VERSION ""

NS_ :

BS_:

BU_:

BO_ 2568814450 Sevcon_2_HS5: 8 Vector__XXX
 SG_ Sevcon_2_EncoderAngle : 0|32@1- (0.00001525,0) [0|0] "" Vector__XXX

BO_ 2568683378 Sevcon_2_HS3: 8 Vector__XXX
 SG_ Sevcon_2_HeatSinkTemp : 0|16@1- (1,0) [0|0] "" Vector__XXX
 SG_ Sevcon_2_RemainingTemp : 16|16@1- (1,0) [0|0] "" Vector__XXX
 SG_ Sevcon_2_CapVoltage : 32|16@1- (0.0625,0) [0|0] "" Vector__XXX

BO_ 2568617842 Sevcon_2_HS2: 8 Vector__XXX
 SG_ Sevcon_2_StatusWord : 32|16@1- (1,0) [0|0] "" Vector__XXX

BO_ 2568552306 Sevcon_2_HS1: 8 Vector__XXX
 SG_ Sevcon_2_OutputTorque : 0|16@1- (0.0625,0) [0|0] "" Vector__XXX
 SG_ Sevcon_2_Speed : 16|16@1- (1,0) [0|0] "" Vector__XXX
 SG_ Sevcon_2_BatteryCurrent : 32|16@1- (1,0) [0|0] "" Vector__XXX

BO_ 2568814449 Sevcon_1_HS5: 8 Vector__XXX
 SG_ Sevcon_1_EncoderAngle : 0|32@1- (0.00001525,0) [0|0] "" Vector__XXX

BO_ 2568683377 Sevcon_1_HS3: 8 Vector__XXX
 SG_ Sevcon_1_HeatSinkTemp : 0|16@1- (1,0) [0|0] "" Vector__XXX
 SG_ Sevcon_1_RemainingTemp : 16|16@1- (1,0) [0|0] "" Vector__XXX
 SG_ Sevcon_1_CapVoltage : 32|16@1- (0.0625,0) [0|0] "" Vector__XXX

BO_ 2568617841 Sevcon_1_HS2: 8 Vector__XXX
 SG_ Sevcon_1_StatusWord : 32|16@1- (1,0) [0|0] "" Vector__XXX

BO_ 2568552305 Sevcon_1_HS1: 8 Vector__XXX
 SG_ Sevcon_1_OutputTorque : 0|16@1- (0.0625,0) [0|0] "" Vector__XXX
 SG_ Sevcon_1_Speed : 16|16@1- (1,0) [0|0] "" Vector__XXX
 SG_ Sevcon_1_BatteryCurrent : 32|16@1- (1,0) [0|0] "" Vector__XXX

BO_ 2290122920 VCU_Temp_Gearbox_Right: 8 Vector__XXX
 SG_ VCU_Gearbox_Temp_Right_Temp : 39|16@0+ (1,0) [0|0] "" Vector__XXX
 SG_ VCU_Gearbox_Temp_Right_R : 23|16@0+ (1,0) [0|0] "" Vector__XXX
 SG_ VCU_Gearbox_Temp_Right_ADC : 7|16@0+ (1,0) [0|0] "" Vector__XXX

BO_ 2290122919 VCU_Temp_Gearbox_Left: 8 Vector__XXX
 SG_ VCU_Gearbox_Temp_Left_Temp : 39|16@0+ (1,0) [0|0] "" Vector__XXX
 SG_ VCU_Gearbox_Temp_Left_R : 23|16@0+ (1,0) [0|0] "" Vector__XXX
 SG_ VCU_Gearbox_Temp_Left_ADC : 7|16@0+ (1,0) [0|0] "" Vector__XXX

BO_ 2290122832 VCU_AirPressure: 8 Vector__XXX
 SG_ VCU_AirPressure_ADC : 7|16@0+ (1,0) [0|0] "" Vector__XXX

BO_ 2420424705 MCISO_Heartbeat_Right: 8 Vector__XXX
 SG_ MCISO_HeartbeatState_Right : 0|16@1+ (1,0) [0|0] "" Vector__XXX

BO_ 2420424704 MCISO_Heartbeat_Left: 8 Vector__XXX
 SG_ MCISO_HeartbeatState_Left : 0|16@1+ (1,0) [0|0] "" Vector__XXX

BO_ 2424619008 SW_Heartbeat: 8 Vector__XXX
 SG_ SW_Heartbeat_Flags : 16|16@1+ (1,0) [0|0] "" Vector__XXX
 SG_ SW_Heartbeat_State : 0|8@1+ (1,0) [0|0] "" Vector__XXX
 SG_ SW_Heartbeat_MissionID : 8|8@1+ (1,0) [0|0] "" Vector__XXX

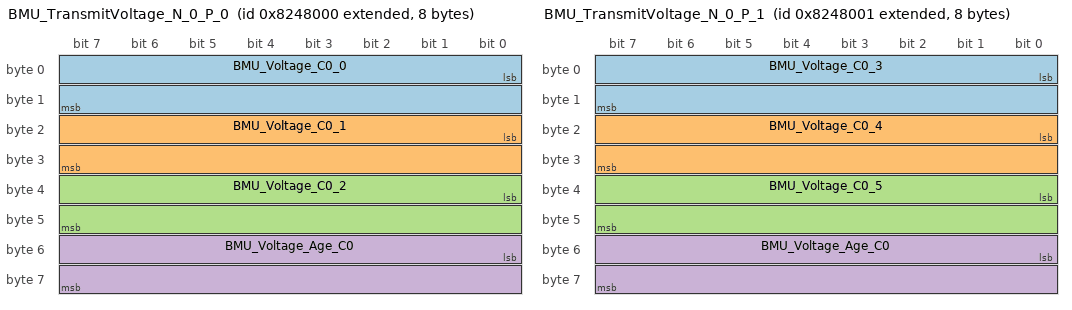
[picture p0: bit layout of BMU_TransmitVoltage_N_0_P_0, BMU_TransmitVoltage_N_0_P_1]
BO_ 2284093440 BMU_TransmitVoltage_N_0_P_0: 8 Vector__XXX
 SG_ BMU_Voltage_C0_0 : 0|16@1+ (1,0) [0|0] "" Vector__XXX
 SG_ BMU_Voltage_C0_1 : 16|16@1+ (1,0) [0|0] "" Vector__XXX
 SG_ BMU_Voltage_C0_2 : 32|16@1+ (1,0) [0|0] "" Vector__XXX
 SG_ BMU_Voltage_Age_C0 : 48|16@1+ (1,0) [0|0] "" Vector__XXX

BO_ 2284093441 BMU_TransmitVoltage_N_0_P_1: 8 Vector__XXX
 SG_ BMU_Voltage_C0_3 : 0|16@1+ (1,0) [0|0] "" Vector__XXX
 SG_ BMU_Voltage_C0_4 : 16|16@1+ (1,0) [0|0] "" Vector__XXX
 SG_ BMU_Voltage_C0_5 : 32|16@1+ (1,0) [0|0] "" Vector__XXX
 SG_ BMU_Voltage_Age_C0 : 48|16@1+ (1,0) [0|0] "" Vector__XXX

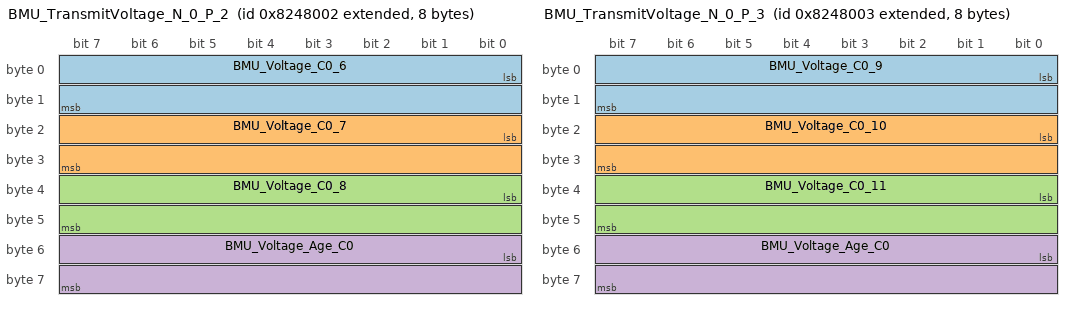
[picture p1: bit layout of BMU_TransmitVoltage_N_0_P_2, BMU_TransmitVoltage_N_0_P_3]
BO_ 2284093442 BMU_TransmitVoltage_N_0_P_2: 8 Vector__XXX
 SG_ BMU_Voltage_C0_6 : 0|16@1+ (1,0) [0|0] "" Vector__XXX
 SG_ BMU_Voltage_C0_7 : 16|16@1+ (1,0) [0|0] "" Vector__XXX
 SG_ BMU_Voltage_C0_8 : 32|16@1+ (1,0) [0|0] "" Vector__XXX
 SG_ BMU_Voltage_Age_C0 : 48|16@1+ (1,0) [0|0] "" Vector__XXX

BO_ 2284093443 BMU_TransmitVoltage_N_0_P_3: 8 Vector__XXX
 SG_ BMU_Voltage_C0_9 : 0|16@1+ (1,0) [0|0] "" Vector__XXX
 SG_ BMU_Voltage_C0_10 : 16|16@1+ (1,0) [0|0] "" Vector__XXX
 SG_ BMU_Voltage_C0_11 : 32|16@1+ (1,0) [0|0] "" Vector__XXX
 SG_ BMU_Voltage_Age_C0 : 48|16@1+ (1,0) [0|0] "" Vector__XXX

BO_ 2284093444 BMU_TransmitVoltage_N_0_P_4: 8 Vector__XXX
 SG_ BMU_Voltage_C0_12 : 0|16@1+ (1,0) [0|0] "" Vector__XXX
 SG_ BMU_Voltage_C0_13 : 16|16@1+ (1,0) [0|0] "" Vector__XXX
 SG_ BMU_Voltage_Age_C0 : 48|16@1+ (1,0) [0|0] "" Vector__XXX

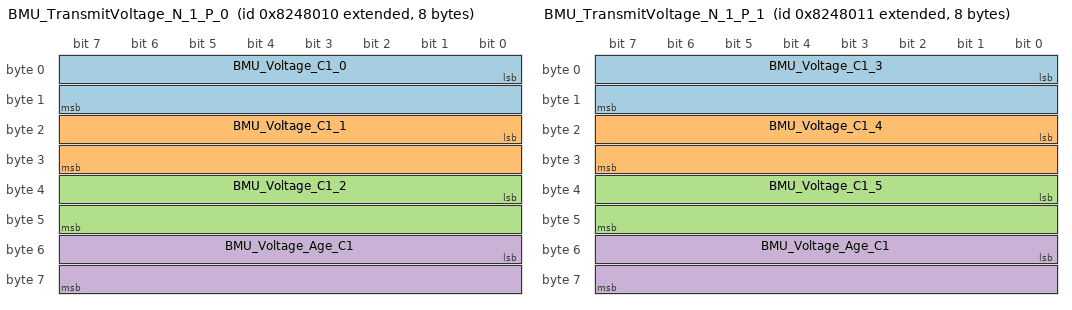
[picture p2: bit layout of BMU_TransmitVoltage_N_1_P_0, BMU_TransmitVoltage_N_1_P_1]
BO_ 2284093456 BMU_TransmitVoltage_N_1_P_0: 8 Vector__XXX
 SG_ BMU_Voltage_C1_0 : 0|16@1+ (1,0) [0|0] "" Vector__XXX
 SG_ BMU_Voltage_C1_1 : 16|16@1+ (1,0) [0|0] "" Vector__XXX
 SG_ BMU_Voltage_C1_2 : 32|16@1+ (1,0) [0|0] "" Vector__XXX
 SG_ BMU_Voltage_Age_C1 : 48|16@1+ (1,0) [0|0] "" Vector__XXX

BO_ 2284093457 BMU_TransmitVoltage_N_1_P_1: 8 Vector__XXX
 SG_ BMU_Voltage_C1_3 : 0|16@1+ (1,0) [0|0] "" Vector__XXX
 SG_ BMU_Voltage_C1_4 : 16|16@1+ (1,0) [0|0] "" Vector__XXX
 SG_ BMU_Voltage_C1_5 : 32|16@1+ (1,0) [0|0] "" Vector__XXX
 SG_ BMU_Voltage_Age_C1 : 48|16@1+ (1,0) [0|0] "" Vector__XXX

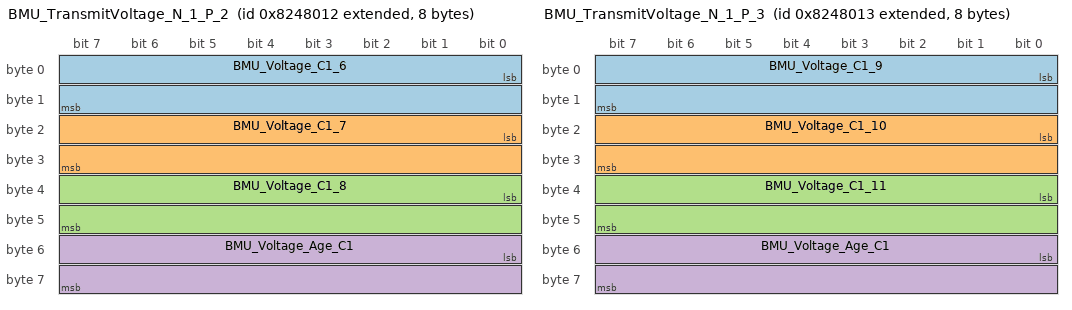
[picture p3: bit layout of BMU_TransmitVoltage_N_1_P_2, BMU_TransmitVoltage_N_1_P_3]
BO_ 2284093458 BMU_TransmitVoltage_N_1_P_2: 8 Vector__XXX
 SG_ BMU_Voltage_C1_6 : 0|16@1+ (1,0) [0|0] "" Vector__XXX
 SG_ BMU_Voltage_C1_7 : 16|16@1+ (1,0) [0|0] "" Vector__XXX
 SG_ BMU_Voltage_C1_8 : 32|16@1+ (1,0) [0|0] "" Vector__XXX
 SG_ BMU_Voltage_Age_C1 : 48|16@1+ (1,0) [0|0] "" Vector__XXX

BO_ 2284093459 BMU_TransmitVoltage_N_1_P_3: 8 Vector__XXX
 SG_ BMU_Voltage_C1_9 : 0|16@1+ (1,0) [0|0] "" Vector__XXX
 SG_ BMU_Voltage_C1_10 : 16|16@1+ (1,0) [0|0] "" Vector__XXX
 SG_ BMU_Voltage_C1_11 : 32|16@1+ (1,0) [0|0] "" Vector__XXX
 SG_ BMU_Voltage_Age_C1 : 48|16@1+ (1,0) [0|0] "" Vector__XXX

BO_ 2284093460 BMU_TransmitVoltage_N_1_P_4: 8 Vector__XXX
 SG_ BMU_Voltage_C1_12 : 0|16@1+ (1,0) [0|0] "" Vector__XXX
 SG_ BMU_Voltage_C1_13 : 16|16@1+ (1,0) [0|0] "" Vector__XXX
 SG_ BMU_Voltage_Age_C1 : 48|16@1+ (1,0) [0|0] "" Vector__XXX

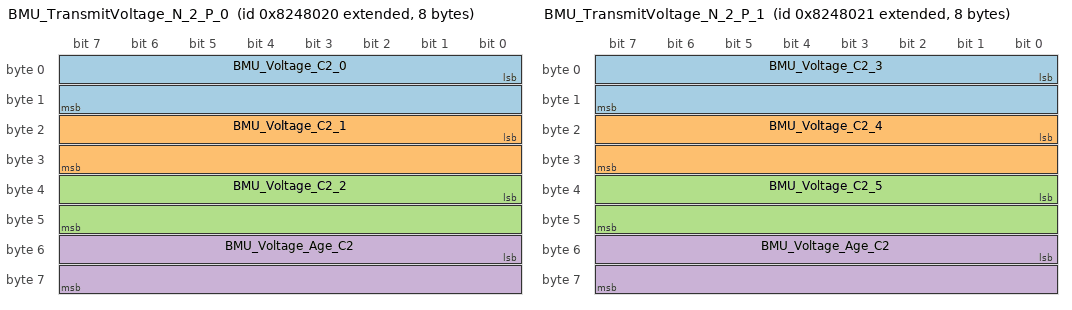
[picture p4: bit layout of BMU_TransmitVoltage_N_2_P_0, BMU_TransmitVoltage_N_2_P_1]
BO_ 2284093472 BMU_TransmitVoltage_N_2_P_0: 8 Vector__XXX
 SG_ BMU_Voltage_C2_0 : 0|16@1+ (1,0) [0|0] "" Vector__XXX
 SG_ BMU_Voltage_C2_1 : 16|16@1+ (1,0) [0|0] "" Vector__XXX
 SG_ BMU_Voltage_C2_2 : 32|16@1+ (1,0) [0|0] "" Vector__XXX
 SG_ BMU_Voltage_Age_C2 : 48|16@1+ (1,0) [0|0] "" Vector__XXX

BO_ 2284093473 BMU_TransmitVoltage_N_2_P_1: 8 Vector__XXX
 SG_ BMU_Voltage_C2_3 : 0|16@1+ (1,0) [0|0] "" Vector__XXX
 SG_ BMU_Voltage_C2_4 : 16|16@1+ (1,0) [0|0] "" Vector__XXX
 SG_ BMU_Voltage_C2_5 : 32|16@1+ (1,0) [0|0] "" Vector__XXX
 SG_ BMU_Voltage_Age_C2 : 48|16@1+ (1,0) [0|0] "" Vector__XXX

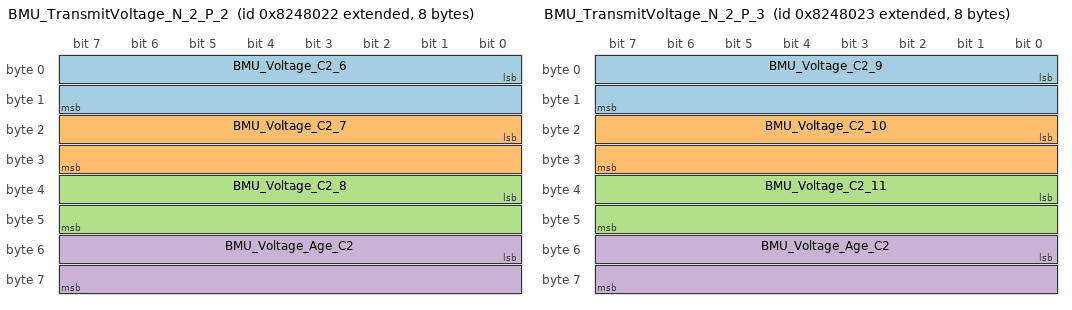
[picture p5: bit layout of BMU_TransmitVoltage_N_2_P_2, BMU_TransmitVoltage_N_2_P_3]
BO_ 2284093474 BMU_TransmitVoltage_N_2_P_2: 8 Vector__XXX
 SG_ BMU_Voltage_C2_6 : 0|16@1+ (1,0) [0|0] "" Vector__XXX
 SG_ BMU_Voltage_C2_7 : 16|16@1+ (1,0) [0|0] "" Vector__XXX
 SG_ BMU_Voltage_C2_8 : 32|16@1+ (1,0) [0|0] "" Vector__XXX
 SG_ BMU_Voltage_Age_C2 : 48|16@1+ (1,0) [0|0] "" Vector__XXX

BO_ 2284093475 BMU_TransmitVoltage_N_2_P_3: 8 Vector__XXX
 SG_ BMU_Voltage_C2_9 : 0|16@1+ (1,0) [0|0] "" Vector__XXX
 SG_ BMU_Voltage_C2_10 : 16|16@1+ (1,0) [0|0] "" Vector__XXX
 SG_ BMU_Voltage_C2_11 : 32|16@1+ (1,0) [0|0] "" Vector__XXX
 SG_ BMU_Voltage_Age_C2 : 48|16@1+ (1,0) [0|0] "" Vector__XXX

BO_ 2284093476 BMU_TransmitVoltage_N_2_P_4: 8 Vector__XXX
 SG_ BMU_Voltage_C2_12 : 0|16@1+ (1,0) [0|0] "" Vector__XXX
 SG_ BMU_Voltage_C2_13 : 16|16@1+ (1,0) [0|0] "" Vector__XXX
 SG_ BMU_Voltage_Age_C2 : 48|16@1+ (1,0) [0|0] "" Vector__XXX

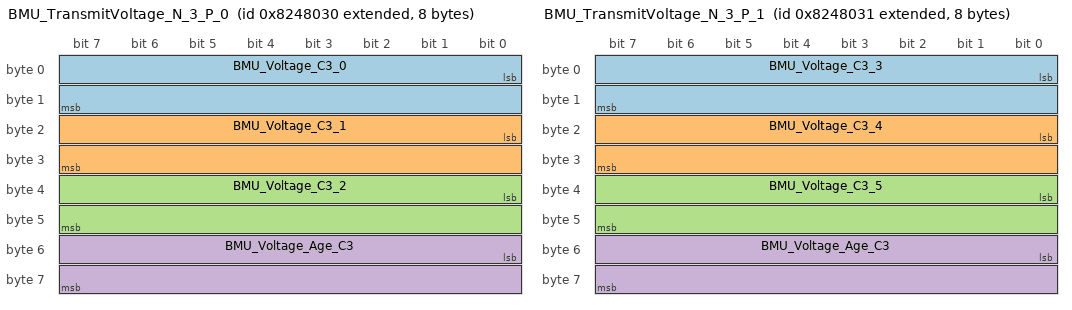
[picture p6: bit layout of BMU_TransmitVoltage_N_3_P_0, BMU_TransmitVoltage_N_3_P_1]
BO_ 2284093488 BMU_TransmitVoltage_N_3_P_0: 8 Vector__XXX
 SG_ BMU_Voltage_C3_0 : 0|16@1+ (1,0) [0|0] "" Vector__XXX
 SG_ BMU_Voltage_C3_1 : 16|16@1+ (1,0) [0|0] "" Vector__XXX
 SG_ BMU_Voltage_C3_2 : 32|16@1+ (1,0) [0|0] "" Vector__XXX
 SG_ BMU_Voltage_Age_C3 : 48|16@1+ (1,0) [0|0] "" Vector__XXX

BO_ 2284093489 BMU_TransmitVoltage_N_3_P_1: 8 Vector__XXX
 SG_ BMU_Voltage_C3_3 : 0|16@1+ (1,0) [0|0] "" Vector__XXX
 SG_ BMU_Voltage_C3_4 : 16|16@1+ (1,0) [0|0] "" Vector__XXX
 SG_ BMU_Voltage_C3_5 : 32|16@1+ (1,0) [0|0] "" Vector__XXX
 SG_ BMU_Voltage_Age_C3 : 48|16@1+ (1,0) [0|0] "" Vector__XXX

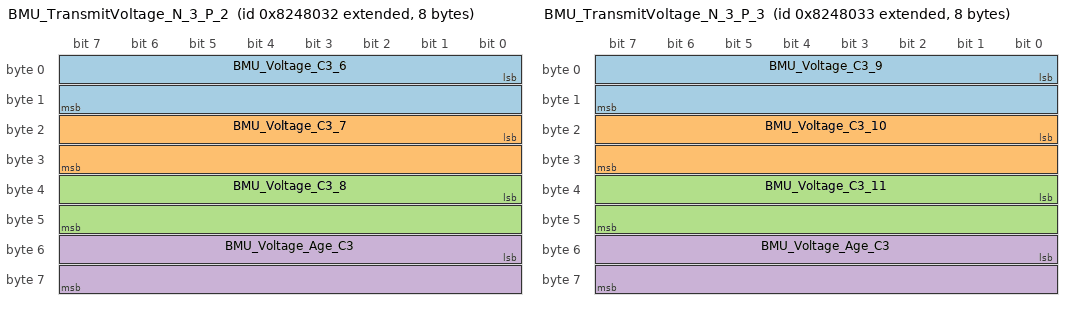
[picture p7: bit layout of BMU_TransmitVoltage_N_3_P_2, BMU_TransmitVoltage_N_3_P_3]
BO_ 2284093490 BMU_TransmitVoltage_N_3_P_2: 8 Vector__XXX
 SG_ BMU_Voltage_C3_6 : 0|16@1+ (1,0) [0|0] "" Vector__XXX
 SG_ BMU_Voltage_C3_7 : 16|16@1+ (1,0) [0|0] "" Vector__XXX
 SG_ BMU_Voltage_C3_8 : 32|16@1+ (1,0) [0|0] "" Vector__XXX
 SG_ BMU_Voltage_Age_C3 : 48|16@1+ (1,0) [0|0] "" Vector__XXX

BO_ 2284093491 BMU_TransmitVoltage_N_3_P_3: 8 Vector__XXX
 SG_ BMU_Voltage_C3_9 : 0|16@1+ (1,0) [0|0] "" Vector__XXX
 SG_ BMU_Voltage_C3_10 : 16|16@1+ (1,0) [0|0] "" Vector__XXX
 SG_ BMU_Voltage_C3_11 : 32|16@1+ (1,0) [0|0] "" Vector__XXX
 SG_ BMU_Voltage_Age_C3 : 48|16@1+ (1,0) [0|0] "" Vector__XXX

BO_ 2284093492 BMU_TransmitVoltage_N_3_P_4: 8 Vector__XXX
 SG_ BMU_Voltage_C3_12 : 0|16@1+ (1,0) [0|0] "" Vector__XXX
 SG_ BMU_Voltage_C3_13 : 16|16@1+ (1,0) [0|0] "" Vector__XXX
 SG_ BMU_Voltage_Age_C3 : 48|16@1+ (1,0) [0|0] "" Vector__XXX

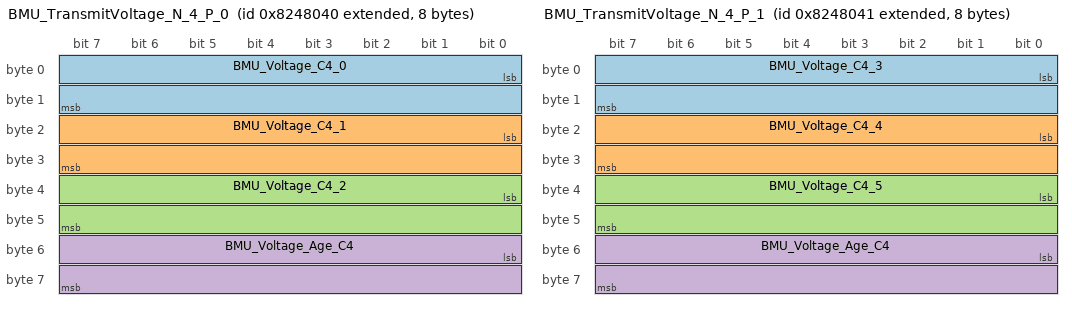
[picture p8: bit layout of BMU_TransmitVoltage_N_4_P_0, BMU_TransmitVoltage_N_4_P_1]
BO_ 2284093504 BMU_TransmitVoltage_N_4_P_0: 8 Vector__XXX
 SG_ BMU_Voltage_C4_0 : 0|16@1+ (1,0) [0|0] "" Vector__XXX
 SG_ BMU_Voltage_C4_1 : 16|16@1+ (1,0) [0|0] "" Vector__XXX
 SG_ BMU_Voltage_C4_2 : 32|16@1+ (1,0) [0|0] "" Vector__XXX
 SG_ BMU_Voltage_Age_C4 : 48|16@1+ (1,0) [0|0] "" Vector__XXX

BO_ 2284093505 BMU_TransmitVoltage_N_4_P_1: 8 Vector__XXX
 SG_ BMU_Voltage_C4_3 : 0|16@1+ (1,0) [0|0] "" Vector__XXX
 SG_ BMU_Voltage_C4_4 : 16|16@1+ (1,0) [0|0] "" Vector__XXX
 SG_ BMU_Voltage_C4_5 : 32|16@1+ (1,0) [0|0] "" Vector__XXX
 SG_ BMU_Voltage_Age_C4 : 48|16@1+ (1,0) [0|0] "" Vector__XXX

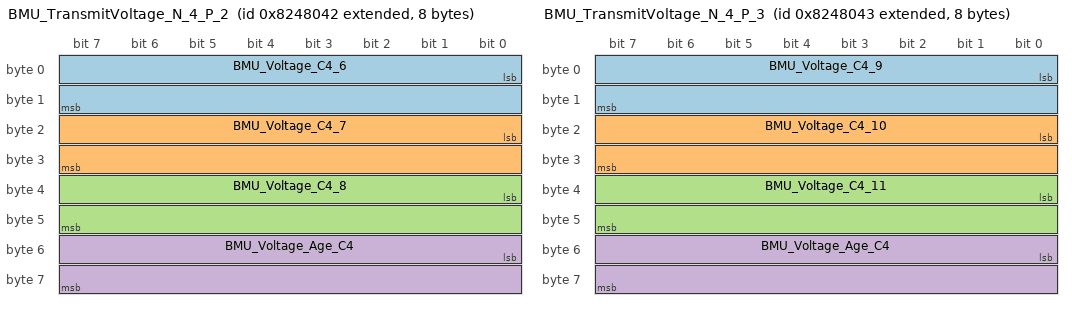
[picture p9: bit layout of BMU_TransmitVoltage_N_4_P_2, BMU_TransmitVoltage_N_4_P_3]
BO_ 2284093506 BMU_TransmitVoltage_N_4_P_2: 8 Vector__XXX
 SG_ BMU_Voltage_C4_6 : 0|16@1+ (1,0) [0|0] "" Vector__XXX
 SG_ BMU_Voltage_C4_7 : 16|16@1+ (1,0) [0|0] "" Vector__XXX
 SG_ BMU_Voltage_C4_8 : 32|16@1+ (1,0) [0|0] "" Vector__XXX
 SG_ BMU_Voltage_Age_C4 : 48|16@1+ (1,0) [0|0] "" Vector__XXX

BO_ 2284093507 BMU_TransmitVoltage_N_4_P_3: 8 Vector__XXX
 SG_ BMU_Voltage_C4_9 : 0|16@1+ (1,0) [0|0] "" Vector__XXX
 SG_ BMU_Voltage_C4_10 : 16|16@1+ (1,0) [0|0] "" Vector__XXX
 SG_ BMU_Voltage_C4_11 : 32|16@1+ (1,0) [0|0] "" Vector__XXX
 SG_ BMU_Voltage_Age_C4 : 48|16@1+ (1,0) [0|0] "" Vector__XXX

BO_ 2284093508 BMU_TransmitVoltage_N_4_P_4: 8 Vector__XXX
 SG_ BMU_Voltage_C4_12 : 0|16@1+ (1,0) [0|0] "" Vector__XXX
 SG_ BMU_Voltage_C4_13 : 16|16@1+ (1,0) [0|0] "" Vector__XXX
 SG_ BMU_Voltage_Age_C4 : 48|16@1+ (1,0) [0|0] "" Vector__XXX

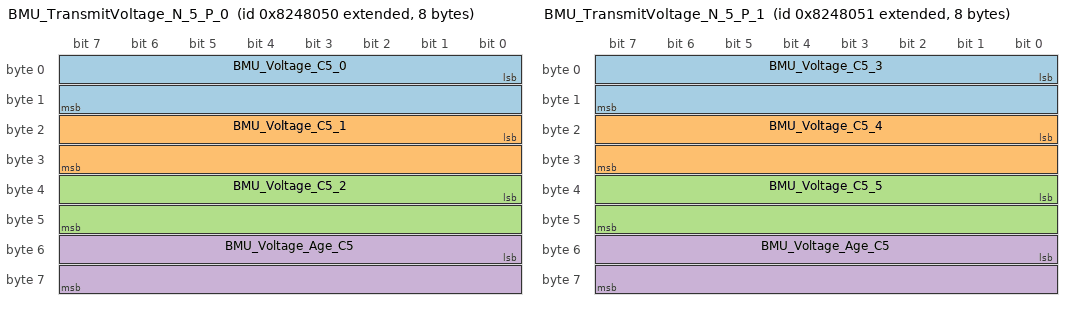
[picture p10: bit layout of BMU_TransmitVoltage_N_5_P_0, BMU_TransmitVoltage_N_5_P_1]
BO_ 2284093520 BMU_TransmitVoltage_N_5_P_0: 8 Vector__XXX
 SG_ BMU_Voltage_C5_0 : 0|16@1+ (1,0) [0|0] "" Vector__XXX
 SG_ BMU_Voltage_C5_1 : 16|16@1+ (1,0) [0|0] "" Vector__XXX
 SG_ BMU_Voltage_C5_2 : 32|16@1+ (1,0) [0|0] "" Vector__XXX
 SG_ BMU_Voltage_Age_C5 : 48|16@1+ (1,0) [0|0] "" Vector__XXX

BO_ 2284093521 BMU_TransmitVoltage_N_5_P_1: 8 Vector__XXX
 SG_ BMU_Voltage_C5_3 : 0|16@1+ (1,0) [0|0] "" Vector__XXX
 SG_ BMU_Voltage_C5_4 : 16|16@1+ (1,0) [0|0] "" Vector__XXX
 SG_ BMU_Voltage_C5_5 : 32|16@1+ (1,0) [0|0] "" Vector__XXX
 SG_ BMU_Voltage_Age_C5 : 48|16@1+ (1,0) [0|0] "" Vector__XXX

BO_ 2284093522 BMU_TransmitVoltage_N_5_P_2: 8 Vector__XXX
 SG_ BMU_Voltage_C5_6 : 0|16@1+ (1,0) [0|0] "" Vector__XXX
 SG_ BMU_Voltage_C5_7 : 16|16@1+ (1,0) [0|0] "" Vector__XXX
 SG_ BMU_Voltage_C5_8 : 32|16@1+ (1,0) [0|0] "" Vector__XXX
 SG_ BMU_Voltage_Age_C5 : 48|16@1+ (1,0) [0|0] "" Vector__XXX

BO_ 2284093523 BMU_TransmitVoltage_N_5_P_3: 8 Vector__XXX
 SG_ BMU_Voltage_C5_9 : 0|16@1+ (1,0) [0|0] "" Vector__XXX
 SG_ BMU_Voltage_C5_10 : 16|16@1+ (1,0) [0|0] "" Vector__XXX
 SG_ BMU_Voltage_C5_11 : 32|16@1+ (1,0) [0|0] "" Vector__XXX
 SG_ BMU_Voltage_Age_C5 : 48|16@1+ (1,0) [0|0] "" Vector__XXX

BO_ 2284093524 BMU_TransmitVoltage_N_5_P_4: 8 Vector__XXX
 SG_ BMU_Voltage_C5_12 : 0|16@1+ (1,0) [0|0] "" Vector__XXX
 SG_ BMU_Voltage_C5_13 : 16|16@1+ (1,0) [0|0] "" Vector__XXX
 SG_ BMU_Voltage_Age_C5 : 48|16@1+ (1,0) [0|0] "" Vector__XXX

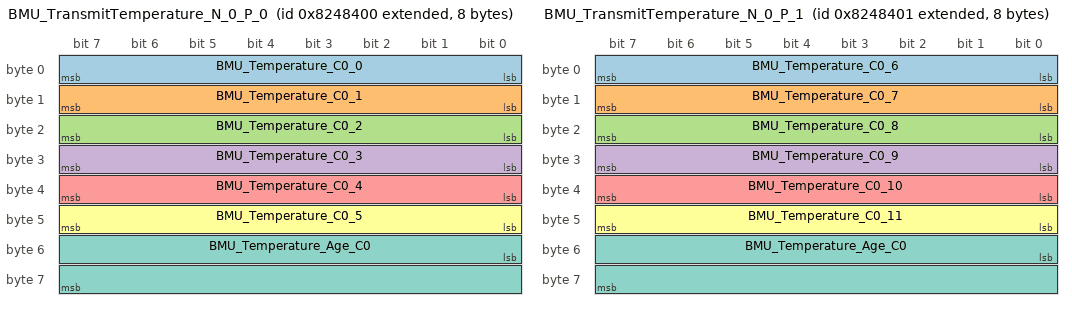
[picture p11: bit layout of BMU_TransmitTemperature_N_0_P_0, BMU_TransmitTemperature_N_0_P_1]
BO_ 2284094464 BMU_TransmitTemperature_N_0_P_0: 8 Vector__XXX
 SG_ BMU_Temperature_C0_0 : 0|8@1+ (1,0) [0|0] "" Vector__XXX
 SG_ BMU_Temperature_C0_1 : 8|8@1+ (1,0) [0|0] "" Vector__XXX
 SG_ BMU_Temperature_C0_2 : 16|8@1+ (1,0) [0|0] "" Vector__XXX
 SG_ BMU_Temperature_C0_3 : 24|8@1+ (1,0) [0|0] "" Vector__XXX
 SG_ BMU_Temperature_C0_4 : 32|8@1+ (1,0) [0|0] "" Vector__XXX
 SG_ BMU_Temperature_C0_5 : 40|8@1+ (1,0) [0|0] "" Vector__XXX
 SG_ BMU_Temperature_Age_C0 : 48|16@1+ (1,0) [0|0] "" Vector__XXX

BO_ 2284094465 BMU_TransmitTemperature_N_0_P_1: 8 Vector__XXX
 SG_ BMU_Temperature_C0_6 : 0|8@1+ (1,0) [0|0] "" Vector__XXX
 SG_ BMU_Temperature_C0_7 : 8|8@1+ (1,0) [0|0] "" Vector__XXX
 SG_ BMU_Temperature_C0_8 : 16|8@1+ (1,0) [0|0] "" Vector__XXX
 SG_ BMU_Temperature_C0_9 : 24|8@1+ (1,0) [0|0] "" Vector__XXX
 SG_ BMU_Temperature_C0_10 : 32|8@1+ (1,0) [0|0] "" Vector__XXX
 SG_ BMU_Temperature_C0_11 : 40|8@1+ (1,0) [0|0] "" Vector__XXX
 SG_ BMU_Temperature_Age_C0 : 48|16@1+ (1,0) [0|0] "" Vector__XXX

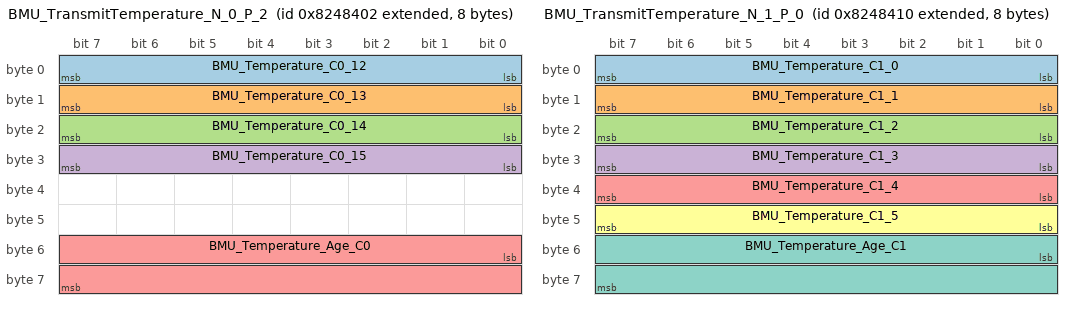
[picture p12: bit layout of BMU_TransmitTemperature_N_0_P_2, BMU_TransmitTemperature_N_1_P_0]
BO_ 2284094466 BMU_TransmitTemperature_N_0_P_2: 8 Vector__XXX
 SG_ BMU_Temperature_C0_12 : 0|8@1+ (1,0) [0|0] "" Vector__XXX
 SG_ BMU_Temperature_C0_13 : 8|8@1+ (1,0) [0|0] "" Vector__XXX
 SG_ BMU_Temperature_C0_14 : 16|8@1+ (1,0) [0|0] "" Vector__XXX
 SG_ BMU_Temperature_C0_15 : 24|8@1+ (1,0) [0|0] "" Vector__XXX
 SG_ BMU_Temperature_Age_C0 : 48|16@1+ (1,0) [0|0] "" Vector__XXX

BO_ 2284094480 BMU_TransmitTemperature_N_1_P_0: 8 Vector__XXX
 SG_ BMU_Temperature_C1_0 : 0|8@1+ (1,0) [0|0] "" Vector__XXX
 SG_ BMU_Temperature_C1_1 : 8|8@1+ (1,0) [0|0] "" Vector__XXX
 SG_ BMU_Temperature_C1_2 : 16|8@1+ (1,0) [0|0] "" Vector__XXX
 SG_ BMU_Temperature_C1_3 : 24|8@1+ (1,0) [0|0] "" Vector__XXX
 SG_ BMU_Temperature_C1_4 : 32|8@1+ (1,0) [0|0] "" Vector__XXX
 SG_ BMU_Temperature_C1_5 : 40|8@1+ (1,0) [0|0] "" Vector__XXX
 SG_ BMU_Temperature_Age_C1 : 48|16@1+ (1,0) [0|0] "" Vector__XXX

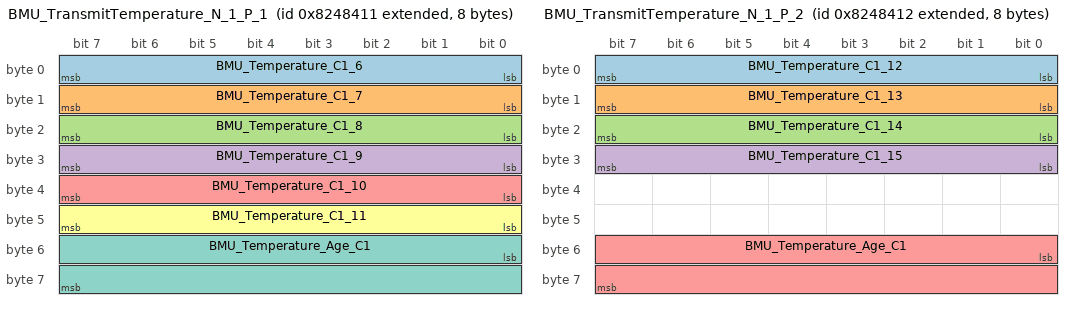
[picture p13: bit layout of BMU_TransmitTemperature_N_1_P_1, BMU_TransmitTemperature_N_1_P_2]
BO_ 2284094481 BMU_TransmitTemperature_N_1_P_1: 8 Vector__XXX
 SG_ BMU_Temperature_C1_6 : 0|8@1+ (1,0) [0|0] "" Vector__XXX
 SG_ BMU_Temperature_C1_7 : 8|8@1+ (1,0) [0|0] "" Vector__XXX
 SG_ BMU_Temperature_C1_8 : 16|8@1+ (1,0) [0|0] "" Vector__XXX
 SG_ BMU_Temperature_C1_9 : 24|8@1+ (1,0) [0|0] "" Vector__XXX
 SG_ BMU_Temperature_C1_10 : 32|8@1+ (1,0) [0|0] "" Vector__XXX
 SG_ BMU_Temperature_C1_11 : 40|8@1+ (1,0) [0|0] "" Vector__XXX
 SG_ BMU_Temperature_Age_C1 : 48|16@1+ (1,0) [0|0] "" Vector__XXX

BO_ 2284094482 BMU_TransmitTemperature_N_1_P_2: 8 Vector__XXX
 SG_ BMU_Temperature_C1_12 : 0|8@1+ (1,0) [0|0] "" Vector__XXX
 SG_ BMU_Temperature_C1_13 : 8|8@1+ (1,0) [0|0] "" Vector__XXX
 SG_ BMU_Temperature_C1_14 : 16|8@1+ (1,0) [0|0] "" Vector__XXX
 SG_ BMU_Temperature_C1_15 : 24|8@1+ (1,0) [0|0] "" Vector__XXX
 SG_ BMU_Temperature_Age_C1 : 48|16@1+ (1,0) [0|0] "" Vector__XXX

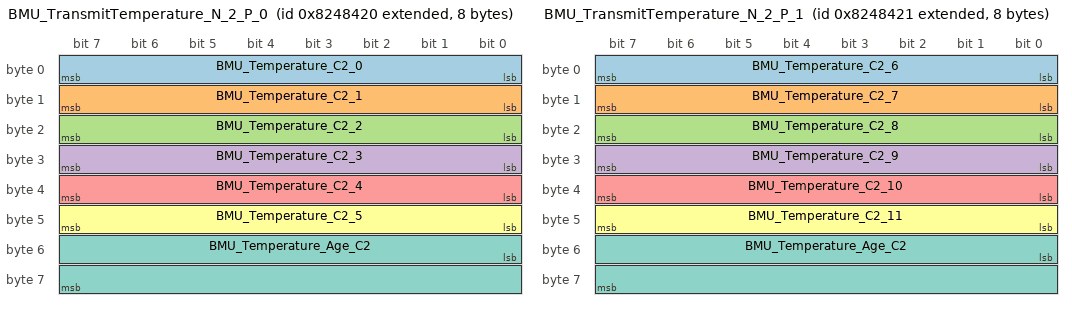
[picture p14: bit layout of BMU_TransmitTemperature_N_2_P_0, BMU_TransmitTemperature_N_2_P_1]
BO_ 2284094496 BMU_TransmitTemperature_N_2_P_0: 8 Vector__XXX
 SG_ BMU_Temperature_C2_0 : 0|8@1+ (1,0) [0|0] "" Vector__XXX
 SG_ BMU_Temperature_C2_1 : 8|8@1+ (1,0) [0|0] "" Vector__XXX
 SG_ BMU_Temperature_C2_2 : 16|8@1+ (1,0) [0|0] "" Vector__XXX
 SG_ BMU_Temperature_C2_3 : 24|8@1+ (1,0) [0|0] "" Vector__XXX
 SG_ BMU_Temperature_C2_4 : 32|8@1+ (1,0) [0|0] "" Vector__XXX
 SG_ BMU_Temperature_C2_5 : 40|8@1+ (1,0) [0|0] "" Vector__XXX
 SG_ BMU_Temperature_Age_C2 : 48|16@1+ (1,0) [0|0] "" Vector__XXX

BO_ 2284094497 BMU_TransmitTemperature_N_2_P_1: 8 Vector__XXX
 SG_ BMU_Temperature_C2_6 : 0|8@1+ (1,0) [0|0] "" Vector__XXX
 SG_ BMU_Temperature_C2_7 : 8|8@1+ (1,0) [0|0] "" Vector__XXX
 SG_ BMU_Temperature_C2_8 : 16|8@1+ (1,0) [0|0] "" Vector__XXX
 SG_ BMU_Temperature_C2_9 : 24|8@1+ (1,0) [0|0] "" Vector__XXX
 SG_ BMU_Temperature_C2_10 : 32|8@1+ (1,0) [0|0] "" Vector__XXX
 SG_ BMU_Temperature_C2_11 : 40|8@1+ (1,0) [0|0] "" Vector__XXX
 SG_ BMU_Temperature_Age_C2 : 48|16@1+ (1,0) [0|0] "" Vector__XXX

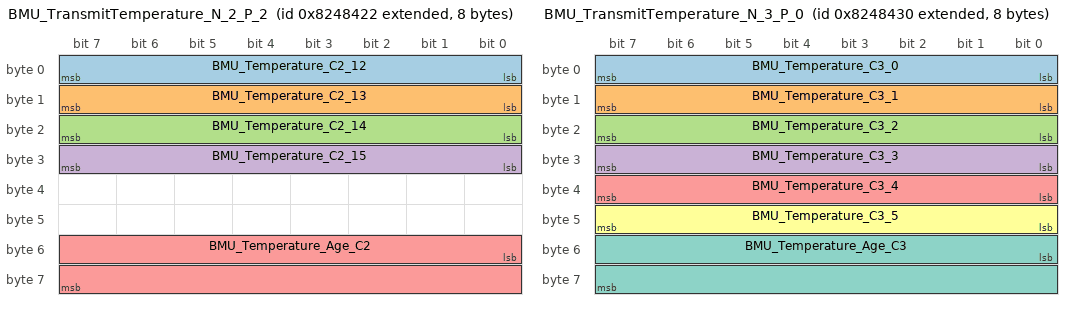
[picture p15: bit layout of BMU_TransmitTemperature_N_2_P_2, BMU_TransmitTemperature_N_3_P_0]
BO_ 2284094498 BMU_TransmitTemperature_N_2_P_2: 8 Vector__XXX
 SG_ BMU_Temperature_C2_12 : 0|8@1+ (1,0) [0|0] "" Vector__XXX
 SG_ BMU_Temperature_C2_13 : 8|8@1+ (1,0) [0|0] "" Vector__XXX
 SG_ BMU_Temperature_C2_14 : 16|8@1+ (1,0) [0|0] "" Vector__XXX
 SG_ BMU_Temperature_C2_15 : 24|8@1+ (1,0) [0|0] "" Vector__XXX
 SG_ BMU_Temperature_Age_C2 : 48|16@1+ (1,0) [0|0] "" Vector__XXX

BO_ 2284094512 BMU_TransmitTemperature_N_3_P_0: 8 Vector__XXX
 SG_ BMU_Temperature_C3_0 : 0|8@1+ (1,0) [0|0] "" Vector__XXX
 SG_ BMU_Temperature_C3_1 : 8|8@1+ (1,0) [0|0] "" Vector__XXX
 SG_ BMU_Temperature_C3_2 : 16|8@1+ (1,0) [0|0] "" Vector__XXX
 SG_ BMU_Temperature_C3_3 : 24|8@1+ (1,0) [0|0] "" Vector__XXX
 SG_ BMU_Temperature_C3_4 : 32|8@1+ (1,0) [0|0] "" Vector__XXX
 SG_ BMU_Temperature_C3_5 : 40|8@1+ (1,0) [0|0] "" Vector__XXX
 SG_ BMU_Temperature_Age_C3 : 48|16@1+ (1,0) [0|0] "" Vector__XXX

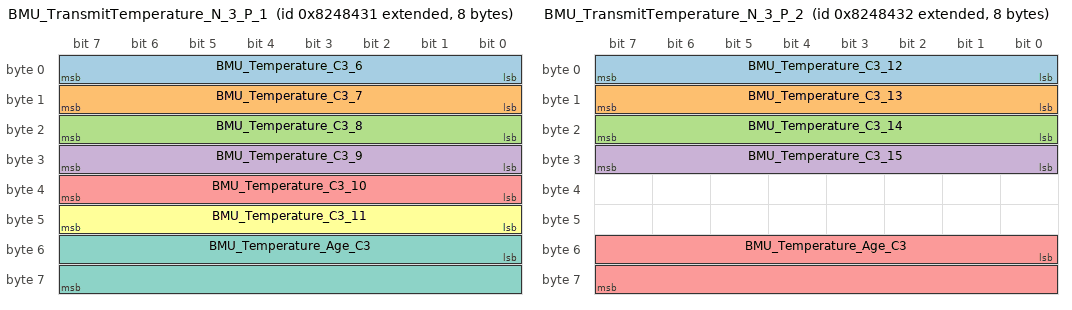
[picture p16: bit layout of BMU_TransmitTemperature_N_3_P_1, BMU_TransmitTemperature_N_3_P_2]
BO_ 2284094513 BMU_TransmitTemperature_N_3_P_1: 8 Vector__XXX
 SG_ BMU_Temperature_C3_6 : 0|8@1+ (1,0) [0|0] "" Vector__XXX
 SG_ BMU_Temperature_C3_7 : 8|8@1+ (1,0) [0|0] "" Vector__XXX
 SG_ BMU_Temperature_C3_8 : 16|8@1+ (1,0) [0|0] "" Vector__XXX
 SG_ BMU_Temperature_C3_9 : 24|8@1+ (1,0) [0|0] "" Vector__XXX
 SG_ BMU_Temperature_C3_10 : 32|8@1+ (1,0) [0|0] "" Vector__XXX
 SG_ BMU_Temperature_C3_11 : 40|8@1+ (1,0) [0|0] "" Vector__XXX
 SG_ BMU_Temperature_Age_C3 : 48|16@1+ (1,0) [0|0] "" Vector__XXX

BO_ 2284094514 BMU_TransmitTemperature_N_3_P_2: 8 Vector__XXX
 SG_ BMU_Temperature_C3_12 : 0|8@1+ (1,0) [0|0] "" Vector__XXX
 SG_ BMU_Temperature_C3_13 : 8|8@1+ (1,0) [0|0] "" Vector__XXX
 SG_ BMU_Temperature_C3_14 : 16|8@1+ (1,0) [0|0] "" Vector__XXX
 SG_ BMU_Temperature_C3_15 : 24|8@1+ (1,0) [0|0] "" Vector__XXX
 SG_ BMU_Temperature_Age_C3 : 48|16@1+ (1,0) [0|0] "" Vector__XXX

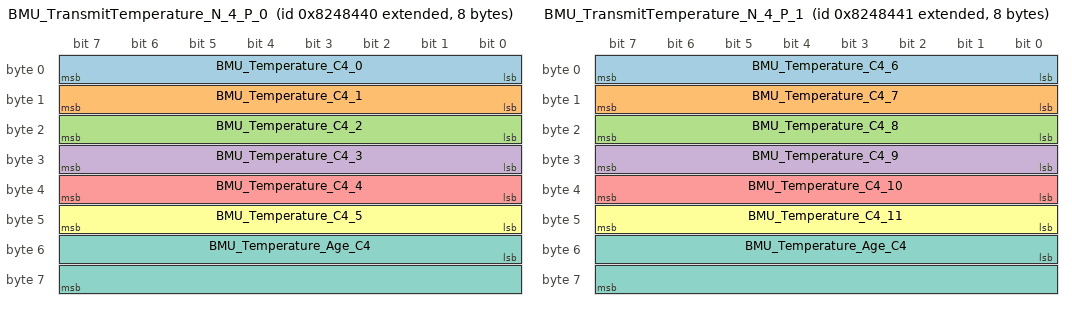
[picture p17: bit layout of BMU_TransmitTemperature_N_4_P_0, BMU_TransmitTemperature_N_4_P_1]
BO_ 2284094528 BMU_TransmitTemperature_N_4_P_0: 8 Vector__XXX
 SG_ BMU_Temperature_C4_0 : 0|8@1+ (1,0) [0|0] "" Vector__XXX
 SG_ BMU_Temperature_C4_1 : 8|8@1+ (1,0) [0|0] "" Vector__XXX
 SG_ BMU_Temperature_C4_2 : 16|8@1+ (1,0) [0|0] "" Vector__XXX
 SG_ BMU_Temperature_C4_3 : 24|8@1+ (1,0) [0|0] "" Vector__XXX
 SG_ BMU_Temperature_C4_4 : 32|8@1+ (1,0) [0|0] "" Vector__XXX
 SG_ BMU_Temperature_C4_5 : 40|8@1+ (1,0) [0|0] "" Vector__XXX
 SG_ BMU_Temperature_Age_C4 : 48|16@1+ (1,0) [0|0] "" Vector__XXX

BO_ 2284094529 BMU_TransmitTemperature_N_4_P_1: 8 Vector__XXX
 SG_ BMU_Temperature_C4_6 : 0|8@1+ (1,0) [0|0] "" Vector__XXX
 SG_ BMU_Temperature_C4_7 : 8|8@1+ (1,0) [0|0] "" Vector__XXX
 SG_ BMU_Temperature_C4_8 : 16|8@1+ (1,0) [0|0] "" Vector__XXX
 SG_ BMU_Temperature_C4_9 : 24|8@1+ (1,0) [0|0] "" Vector__XXX
 SG_ BMU_Temperature_C4_10 : 32|8@1+ (1,0) [0|0] "" Vector__XXX
 SG_ BMU_Temperature_C4_11 : 40|8@1+ (1,0) [0|0] "" Vector__XXX
 SG_ BMU_Temperature_Age_C4 : 48|16@1+ (1,0) [0|0] "" Vector__XXX

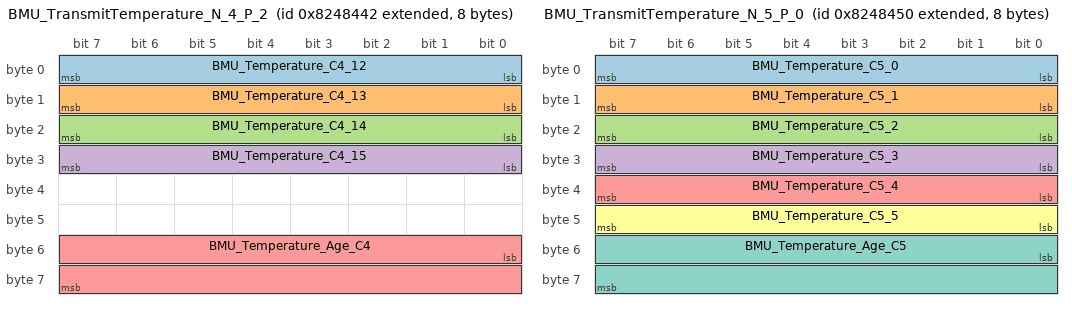
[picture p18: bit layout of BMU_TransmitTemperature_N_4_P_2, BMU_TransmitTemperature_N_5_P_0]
BO_ 2284094530 BMU_TransmitTemperature_N_4_P_2: 8 Vector__XXX
 SG_ BMU_Temperature_C4_12 : 0|8@1+ (1,0) [0|0] "" Vector__XXX
 SG_ BMU_Temperature_C4_13 : 8|8@1+ (1,0) [0|0] "" Vector__XXX
 SG_ BMU_Temperature_C4_14 : 16|8@1+ (1,0) [0|0] "" Vector__XXX
 SG_ BMU_Temperature_C4_15 : 24|8@1+ (1,0) [0|0] "" Vector__XXX
 SG_ BMU_Temperature_Age_C4 : 48|16@1+ (1,0) [0|0] "" Vector__XXX

BO_ 2284094544 BMU_TransmitTemperature_N_5_P_0: 8 Vector__XXX
 SG_ BMU_Temperature_C5_0 : 0|8@1+ (1,0) [0|0] "" Vector__XXX
 SG_ BMU_Temperature_C5_1 : 8|8@1+ (1,0) [0|0] "" Vector__XXX
 SG_ BMU_Temperature_C5_2 : 16|8@1+ (1,0) [0|0] "" Vector__XXX
 SG_ BMU_Temperature_C5_3 : 24|8@1+ (1,0) [0|0] "" Vector__XXX
 SG_ BMU_Temperature_C5_4 : 32|8@1+ (1,0) [0|0] "" Vector__XXX
 SG_ BMU_Temperature_C5_5 : 40|8@1+ (1,0) [0|0] "" Vector__XXX
 SG_ BMU_Temperature_Age_C5 : 48|16@1+ (1,0) [0|0] "" Vector__XXX

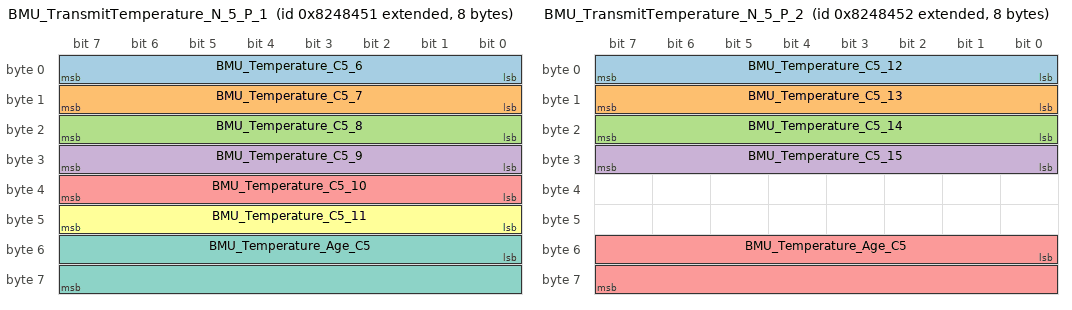
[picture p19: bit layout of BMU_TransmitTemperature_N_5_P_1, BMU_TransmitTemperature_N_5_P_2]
BO_ 2284094545 BMU_TransmitTemperature_N_5_P_1: 8 Vector__XXX
 SG_ BMU_Temperature_C5_6 : 0|8@1+ (1,0) [0|0] "" Vector__XXX
 SG_ BMU_Temperature_C5_7 : 8|8@1+ (1,0) [0|0] "" Vector__XXX
 SG_ BMU_Temperature_C5_8 : 16|8@1+ (1,0) [0|0] "" Vector__XXX
 SG_ BMU_Temperature_C5_9 : 24|8@1+ (1,0) [0|0] "" Vector__XXX
 SG_ BMU_Temperature_C5_10 : 32|8@1+ (1,0) [0|0] "" Vector__XXX
 SG_ BMU_Temperature_C5_11 : 40|8@1+ (1,0) [0|0] "" Vector__XXX
 SG_ BMU_Temperature_Age_C5 : 48|16@1+ (1,0) [0|0] "" Vector__XXX

BO_ 2284094546 BMU_TransmitTemperature_N_5_P_2: 8 Vector__XXX
 SG_ BMU_Temperature_C5_12 : 0|8@1+ (1,0) [0|0] "" Vector__XXX
 SG_ BMU_Temperature_C5_13 : 8|8@1+ (1,0) [0|0] "" Vector__XXX
 SG_ BMU_Temperature_C5_14 : 16|8@1+ (1,0) [0|0] "" Vector__XXX
 SG_ BMU_Temperature_C5_15 : 24|8@1+ (1,0) [0|0] "" Vector__XXX
 SG_ BMU_Temperature_Age_C5 : 48|16@1+ (1,0) [0|0] "" Vector__XXX

BO_ 2290122818 VCU_SuspensionTravel_DASH: 8 Vector__XXX
 SG_ VCU_SuspensionTravel_ADC_FR : 31|16@0+ (1,0) [0|0] "" Vector__XXX
 SG_ VCU_SuspensionTravel_ADC_FL : 15|16@0+ (1,0) [0|0] "" Vector__XXX

BO_ 2290122816 VCU_SuspensionTravel_SHDN: 8 Vector__XXX
 SG_ VCU_SuspensionTravel_ADC_RR : 31|16@0+ (1,0) [0|0] "" Vector__XXX
 SG_ VCU_SuspensionTravel_ADC_RL : 15|16@0+ (1,0) [0|0] "" Vector__XXX

BO_ 2418327552 BMU_Heartbeat: 7 Vector__XXX
 SG_ BMU_Heartbeat_State : 0|56@1+ (1,0) [0|0] "" Vector__XXX

BO_ 2424356864 VCU_Heartbeat_SHDN: 6 Vector__XXX
 SG_ VCU_HeartbeatState_SHDN : 0|48@1+ (1,0) [0|0] "" Vector__XXX

BO_ 2424356865 VCU_Heartbeat_CTRL: 6 Vector__XXX
 SG_ VCU_HeartbeatState_CTRL : 0|48@1+ (1,0) [0|0] "" Vector__XXX

BO_ 2424356866 VCU_Heartbeat_DASH: 6 Vector__XXX
 SG_ VCU_HeartbeatState_DASH : 0|48@1+ (1,0) [0|0] "" Vector__XXX

BO_ 2424356867 VCU_Heartbeat_EBS: 6 Vector__XXX
 SG_ VCU_HeartbeatState_EBS : 0|48@1+ (1,0) [0|0] "" Vector__XXX

BO_ 2424356868 VCU_Heartbeat_ASSI: 6 Vector__XXX
 SG_ VCU_HeartbeatState_ASSI : 0|48@1+ (1,0) [0|0] "" Vector__XXX

BO_ 2424356869 VCU_Heartbeat_EBS_ADC: 6 Vector__XXX
 SG_ VCU_HeartbeatState_EBS_ADC : 0|48@1+ (1,0) [0|0] "" Vector__XXX

BO_ 2290122752 VCU_ShutdownStatus: 3 Vector__XXX
 SG_ VCU_ShutdownStatus : 16|8@1+ (1,0) [0|1] "" Vector__XXX
 SG_ VCU_ShutdownLines : 0|16@1+ (1,0) [0|0] "" Vector__XXX

BO_ 2290122784 VCU_Pedal_Accel: 4 Vector__XXX
 SG_ VCU_Pedal_Accel_1 : 23|16@0+ (1,0) [0|0] "" Vector__XXX
 SG_ VCU_Pedal_Accel_0 : 7|16@0+ (1,0) [0|0] "" Vector__XXX

BO_ 2290122800 VCU_Pedal_Brake: 6 Vector__XXX
 SG_ VCU_Pedal_Brake_ADC_1 : 39|16@0+ (1,0) [0|0] "" Vector__XXX
 SG_ VCU_Pedal_Brake_ADC_0 : 23|16@0+ (1,0) [0|0] "" Vector__XXX
 SG_ VCU_Pedal_Brake : 7|16@0- (1,0) [0|0] "" Vector__XXX

BO_ 2290122848 VCU_TransmitSteering: 8 Vector__XXX
 SG_ VCU_Steering_ADC_1 : 48|16@1+ (1,0) [0|0] "" Vector__XXX
 SG_ VCU_Steering_ADC_0 : 32|16@1+ (1,0) [0|0] "" Vector__XXX
 SG_ VCU_Steering_1 : 16|16@1- (1,0) [0|0] "" Vector__XXX
 SG_ VCU_Steering_0 : 0|16@1- (1,0) [0|0] "" Vector__XXX

BA_DEF_  "BusType" STRING ;
BA_DEF_DEF_  "BusType" "CAN";
